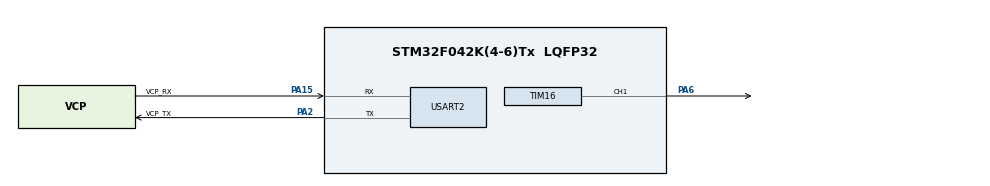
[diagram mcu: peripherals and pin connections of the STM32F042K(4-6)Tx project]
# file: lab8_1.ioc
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Mcu.Family=STM32F0
Mcu.Name=STM32F042K(4-6)Tx
Mcu.Package=LQFP32
PA13.GPIO_Label=SWDIO
PA13.Mode=Serial_Wire
PA13.Signal=SYS_SWDIO
PA14.GPIO_Label=SWCLK
PA14.Mode=Serial_Wire
PA14.Signal=SYS_SWCLK
PA15.GPIO_Label=VCP_RX
PA15.Mode=Asynchronous
PA15.Signal=USART2_RX
PA2.GPIO_Label=VCP_TX
PA2.Mode=Asynchronous
PA2.Signal=USART2_TX
PA6.Signal=S_TIM16_CH1
PF0-OSC_IN.GPIO_Label=MCO
PF0-OSC_IN.Mode=HSE-External-Clock-Source
PF0-OSC_IN.Signal=RCC_OSC_IN
ProjectManager.HeapSize=0x200
ProjectManager.StackSize=0x400
ProjectManager.TargetToolchain=STM32CubeIDE
SH.S_TIM16_CH1.0=TIM16_CH1,PWM Generation1 CH1
TIM16.Channel=TIM_CHANNEL_1
TIM16.Period=256-1
TIM16.Prescaler=80-1
USART2.VirtualMode-Asynchronous=VM_ASYNC
VP_TIM16_VS_ClockSourceINT.Mode=Enable_Timer
board=NUCLEO-F042K6

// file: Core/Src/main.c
/* USER CODE BEGIN Header */
/**
  ******************************************************************************
  * @file           : main.c
  * @brief          : Main program body
  ******************************************************************************
  * @attention
  *
  * Copyright (c) 2025 STMicroelectronics.
  * All rights reserved.
  *
  * This software is licensed under terms that can be found in the LICENSE file
  * in the root directory of this software component.
  * If no LICENSE file comes with this software, it is provided AS-IS.
  *
  ******************************************************************************
  */
/* USER CODE END Header */
#include "main.h"

TIM_HandleTypeDef htim16;

UART_HandleTypeDef huart2;

void SystemClock_Config(void);
static void MX_GPIO_Init(void);
static void MX_USART2_UART_Init(void);
static void MX_TIM16_Init(void);

int main(void)
{

  /* USER CODE BEGIN 1 */
  unsigned int duty_cycle = 0;
  /* USER CODE END 1 */

  /* MCU Configuration--------------------------------------------------------*/

  /* Reset of all peripherals, Initializes the Flash interface and the Systick. */
  HAL_Init();

  /* Configure the system clock */
  SystemClock_Config();

  /* Initialize all configured peripherals */
  MX_GPIO_Init();
  MX_USART2_UART_Init();
  MX_TIM16_Init();
  /* USER CODE BEGIN 2 */
  HAL_TIM_PWM_Start(&htim16, TIM_CHANNEL_1);
  /* USER CODE END 2 */

  /* Infinite loop */
  while (1)
  {
	  for(duty_cycle = 0; duty_cycle < 256; duty_cycle++)
	  {
	  __HAL_TIM_SET_COMPARE(&htim16, TIM_CHANNEL_1, duty_cycle);
	  HAL_Delay(20);
	  }
	  for(duty_cycle = 255; duty_cycle > 0; duty_cycle--)
	  {
	  	  __HAL_TIM_SET_COMPARE(&htim16, TIM_CHANNEL_1, duty_cycle);
	  	  HAL_Delay(20);
	  }
  }
}

void SystemClock_Config(void)
{
  RCC_OscInitTypeDef RCC_OscInitStruct = {0};
  RCC_ClkInitTypeDef RCC_ClkInitStruct = {0};

  /** Initializes the RCC Oscillators according to the specified parameters
  * in the RCC_OscInitTypeDef structure.
  */
  RCC_OscInitStruct.OscillatorType = RCC_OSCILLATORTYPE_HSI;
  RCC_OscInitStruct.HSIState = RCC_HSI_ON;
  RCC_OscInitStruct.HSICalibrationValue = RCC_HSICALIBRATION_DEFAULT;
  RCC_OscInitStruct.PLL.PLLState = RCC_PLL_NONE;
  if (HAL_RCC_OscConfig(&RCC_OscInitStruct) != HAL_OK)
  {
    Error_Handler();
  }

  /** Initializes the CPU, AHB and APB buses clocks
  */
  RCC_ClkInitStruct.ClockType = RCC_CLOCKTYPE_HCLK|RCC_CLOCKTYPE_SYSCLK
                              |RCC_CLOCKTYPE_PCLK1;
  RCC_ClkInitStruct.SYSCLKSource = RCC_SYSCLKSOURCE_HSI;
  RCC_ClkInitStruct.AHBCLKDivider = RCC_SYSCLK_DIV1;
  RCC_ClkInitStruct.APB1CLKDivider = RCC_HCLK_DIV1;

  if (HAL_RCC_ClockConfig(&RCC_ClkInitStruct, FLASH_LATENCY_0) != HAL_OK)
  {
    Error_Handler();
  }
}

static void MX_TIM16_Init(void)
{

  TIM_OC_InitTypeDef sConfigOC = {0};
  TIM_BreakDeadTimeConfigTypeDef sBreakDeadTimeConfig = {0};

  htim16.Instance = TIM16;
  htim16.Init.Prescaler = 80-1;
  htim16.Init.CounterMode = TIM_COUNTERMODE_UP;
  htim16.Init.Period = 256-1;
  htim16.Init.ClockDivision = TIM_CLOCKDIVISION_DIV1;
  htim16.Init.RepetitionCounter = 0;
  htim16.Init.AutoReloadPreload = TIM_AUTORELOAD_PRELOAD_DISABLE;
  if (HAL_TIM_Base_Init(&htim16) != HAL_OK)
  {
    Error_Handler();
  }
  if (HAL_TIM_PWM_Init(&htim16) != HAL_OK)
  {
    Error_Handler();
  }
  sConfigOC.OCMode = TIM_OCMODE_PWM1;
  sConfigOC.Pulse = 0;
  sConfigOC.OCPolarity = TIM_OCPOLARITY_HIGH;
  sConfigOC.OCNPolarity = TIM_OCNPOLARITY_HIGH;
  sConfigOC.OCFastMode = TIM_OCFAST_DISABLE;
  sConfigOC.OCIdleState = TIM_OCIDLESTATE_RESET;
  sConfigOC.OCNIdleState = TIM_OCNIDLESTATE_RESET;
  if (HAL_TIM_PWM_ConfigChannel(&htim16, &sConfigOC, TIM_CHANNEL_1) != HAL_OK)
  {
    Error_Handler();
  }
  sBreakDeadTimeConfig.OffStateRunMode = TIM_OSSR_DISABLE;
  sBreakDeadTimeConfig.OffStateIDLEMode = TIM_OSSI_DISABLE;
  sBreakDeadTimeConfig.LockLevel = TIM_LOCKLEVEL_OFF;
  sBreakDeadTimeConfig.DeadTime = 0;
  sBreakDeadTimeConfig.BreakState = TIM_BREAK_DISABLE;
  sBreakDeadTimeConfig.BreakPolarity = TIM_BREAKPOLARITY_HIGH;
  sBreakDeadTimeConfig.AutomaticOutput = TIM_AUTOMATICOUTPUT_DISABLE;
  if (HAL_TIMEx_ConfigBreakDeadTime(&htim16, &sBreakDeadTimeConfig) != HAL_OK)
  {
    Error_Handler();
  }
  HAL_TIM_MspPostInit(&htim16);

}

static void MX_USART2_UART_Init(void)
{

  huart2.Instance = USART2;
  huart2.Init.BaudRate = 38400;
  huart2.Init.WordLength = UART_WORDLENGTH_8B;
  huart2.Init.StopBits = UART_STOPBITS_1;
  huart2.Init.Parity = UART_PARITY_NONE;
  huart2.Init.Mode = UART_MODE_TX_RX;
  huart2.Init.HwFlowCtl = UART_HWCONTROL_NONE;
  huart2.Init.OverSampling = UART_OVERSAMPLING_16;
  huart2.Init.OneBitSampling = UART_ONE_BIT_SAMPLE_DISABLE;
  huart2.AdvancedInit.AdvFeatureInit = UART_ADVFEATURE_NO_INIT;
  if (HAL_UART_Init(&huart2) != HAL_OK)
  {
    Error_Handler();
  }

}

static void MX_GPIO_Init(void)
{

  /* GPIO Ports Clock Enable */
  __HAL_RCC_GPIOF_CLK_ENABLE();
  __HAL_RCC_GPIOA_CLK_ENABLE();

}

void Error_Handler(void)
{
  __disable_irq();
  while (1)
  {
  }
}
